# STM32F048xx register map
File version: 1.0
Registers are 32-bit, access not given, reset 0x0 unless marked. A register's access mark holds for its fields unless they carry their own. Offsets are from the block's base; [hi:lo] are bit positions; {n}, {i} and the like mark numbered series; 'fields as' and 'values as' point back to an identical list.

## PWR
Base 0x40007000
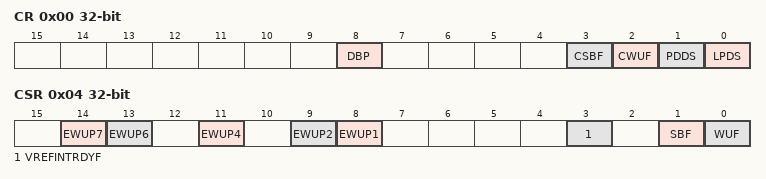
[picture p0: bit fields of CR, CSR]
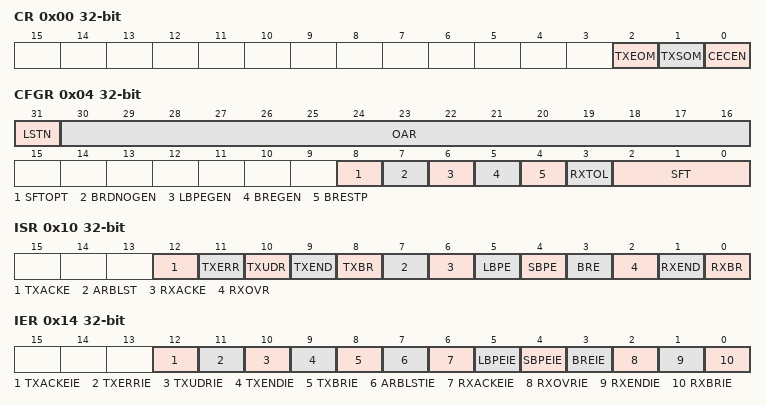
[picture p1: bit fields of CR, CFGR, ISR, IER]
0x00 CR
  [8] DBP, [3] CSBF, [2] CWUF, [1] PDDS, [0] LPDS
0x04 CSR
  [14] EWUP7, [13] EWUP6, [11] EWUP4, [9] EWUP2, [8] EWUP1, [3] VREFINTRDYF, [1] SBF, [0] WUF

## CEC
Base 0x40007800
0x00 CR
  [2] TXEOM, [1] TXSOM, [0] CECEN
0x04 CFGR
  [31] LSTN, [30:16] OAR, [8] SFTOPT, [7] BRDNOGEN, [6] LBPEGEN, [5] BREGEN, [4] BRESTP, [3] RXTOL, [2:0] SFT
0x08 TXDR
  [7:0] TXD
0x0C RXDR
0x10 ISR
  [12] TXACKE, [11] TXERR, [10] TXUDR, [9] TXEND, [8] TXBR, [7] ARBLST, [6] RXACKE, [5] LBPE, [4] SBPE, [3] BRE, [2] RXOVR, [1] RXEND, [0] RXBR
0x14 IER
  [12] TXACKEIE, [11] TXERRIE, [10] TXUDRIE, [9] TXENDIE, [8] TXBRIE, [7] ARBLSTIE, [6] RXACKEIE, [5] LBPEIE, [4] SBPEIE, [3] BREIE, [2] RXOVRIE, [1] RXENDIE, [0] RXBRIE

## SYSCFG
Base 0x40010000
0x00 CFGR1
  [23] I2C_FMP_PA10, [22] I2C_FMP_PA9, [21] I2C_FMP_I2C2, [20] I2C_FMP_I2C1, [n+10] I2C_FMP_PB{n} (n=6..9), [12] TIM17_DMA_RMP, [11] TIM16_DMA_RMP, [10] USART1RX_DMA_RMP, [9] USART1TX_DMA_RMP, [12:8] DMA_RMP, [4] PA11_PA12_RMP, [1:0] MEM_MODE
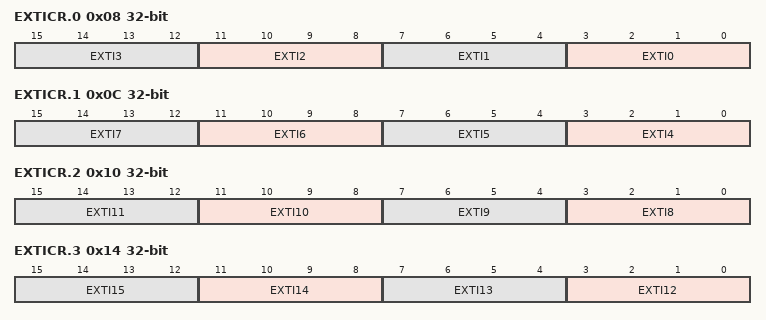
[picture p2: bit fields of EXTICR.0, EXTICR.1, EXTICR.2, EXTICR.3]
0x08 EXTICR.0
  [4n+3:4n] EXTI{n} (n=0..3)
0x0C EXTICR.1
  [4n-13:4n-16] EXTI{n} (n=4..7)
0x10 EXTICR.2
  [4n-29:4n-32] EXTI{n} (n=8..11)
0x14 EXTICR.3
  [4n-45:4n-48] EXTI{n} (n=12..15)
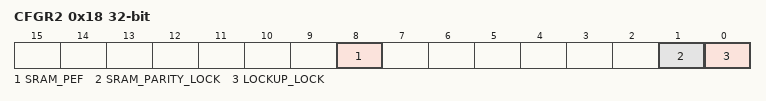
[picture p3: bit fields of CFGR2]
0x18 CFGR2
  [8] SRAM_PEF, [1] SRAM_PARITY_LOCK, [0] LOCKUP_LOCK

## EXTI
Base 0x40010400
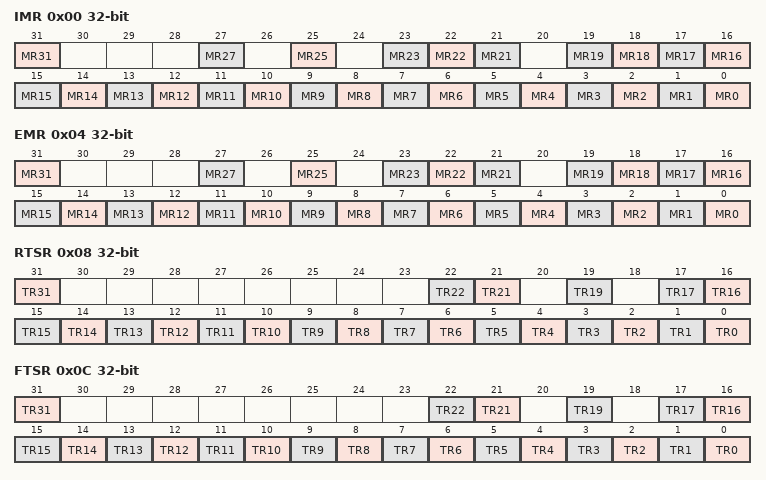
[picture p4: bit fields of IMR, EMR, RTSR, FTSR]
0x00 IMR
  [31] MR31, [27] MR27, [25] MR25, [23] MR23, [22] MR22, [21] MR21, [n] MR{n} (n=0..19)
0x04 EMR
  fields as IMR
0x08 RTSR
  [31] TR31, [22] TR22, [21] TR21, [19] TR19, [n] TR{n} (n=0..17)
0x0C FTSR
  [31] TR31, [22] TR22, [21] TR21, [19] TR19, [n] TR{n} (n=0..17)
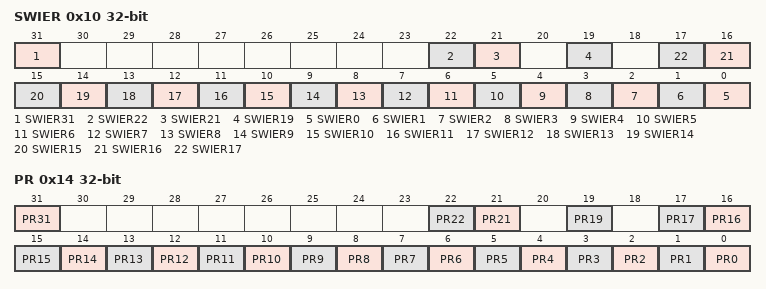
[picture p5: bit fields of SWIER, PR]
0x10 SWIER
  [31] SWIER31, [22] SWIER22, [21] SWIER21, [19] SWIER19, [n] SWIER{n} (n=0..17)
0x14 PR
  [31] PR31, [22] PR22, [21] PR21, [19] PR19, [n] PR{n} (n=0..17)

## ADC1
Base 0x40012400
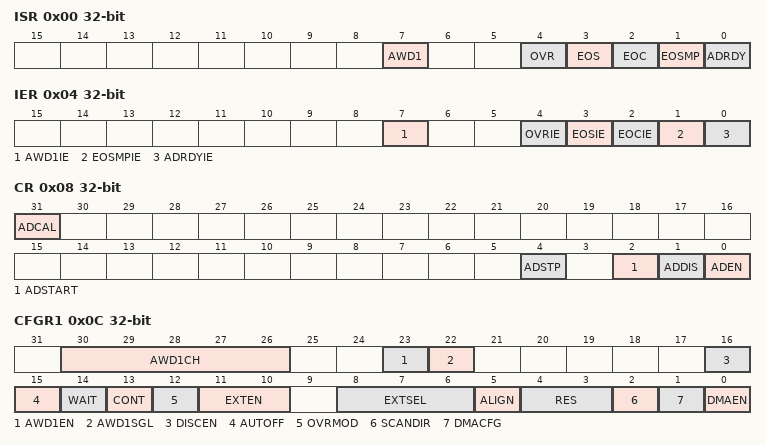
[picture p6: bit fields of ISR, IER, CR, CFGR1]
0x00 ISR
  [7] AWD1, [4] OVR, [3] EOS, [2] EOC, [1] EOSMP, [0] ADRDY
0x04 IER
  [7] AWD1IE, [4] OVRIE, [3] EOSIE, [2] EOCIE, [1] EOSMPIE, [0] ADRDYIE
0x08 CR
  [31] ADCAL, [4] ADSTP, [2] ADSTART, [1] ADDIS, [0] ADEN
0x0C CFGR1
  [30:26] AWD1CH, [23] AWD1EN, [22] AWD1SGL, [16] DISCEN, [15] AUTOFF, [14] WAIT, [13] CONT, [12] OVRMOD, [11:10] EXTEN, [8:6] EXTSEL, [5] ALIGN, [4:3] RES, [2] SCANDIR, [1] DMACFG, [0] DMAEN
0x10 CFGR2
  [31:30] CKMODE
0x14 SMPR
  [2:0] SMP
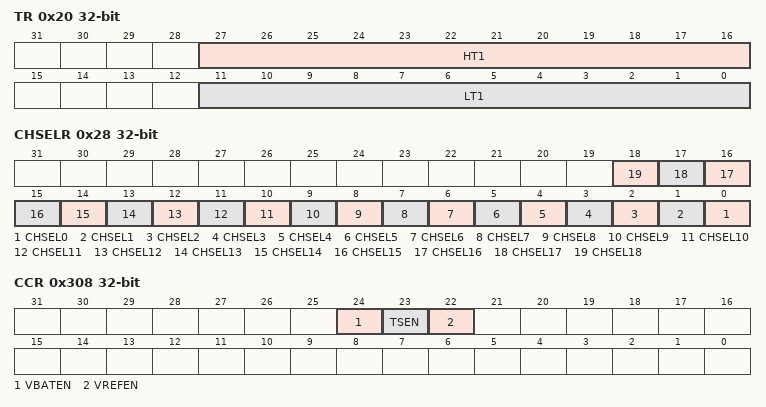
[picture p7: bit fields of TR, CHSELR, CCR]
0x20 TR
  [27:16] HT1, [11:0] LT1
0x28 CHSELR
  [n] CHSEL{n} (n=0..18)
0x40 DR
  [15:0] DATA
0x308 CCR
  [24] VBATEN, [23] TSEN, [22] VREFEN

## DBGMCU
Base 0x40015800
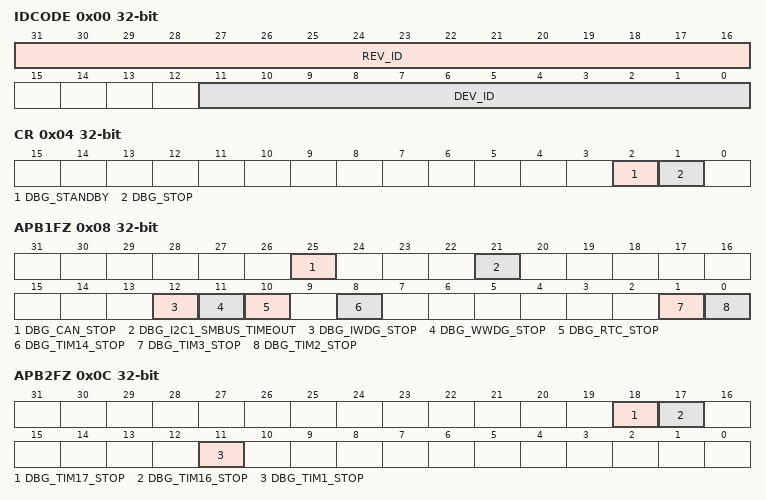
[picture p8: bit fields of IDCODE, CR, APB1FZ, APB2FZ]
0x00 IDCODE
  [31:16] REV_ID, [11:0] DEV_ID
0x04 CR
  [2] DBG_STANDBY, [1] DBG_STOP
0x08 APB1FZ
  [25] DBG_CAN_STOP, [21] DBG_I2C1_SMBUS_TIMEOUT, [12] DBG_IWDG_STOP, [11] DBG_WWDG_STOP, [10] DBG_RTC_STOP, [8] DBG_TIM14_STOP, [1] DBG_TIM3_STOP, [0] DBG_TIM2_STOP
0x0C APB2FZ
  [18] DBG_TIM17_STOP, [17] DBG_TIM16_STOP, [11] DBG_TIM1_STOP

## DMA1
Base 0x40020000
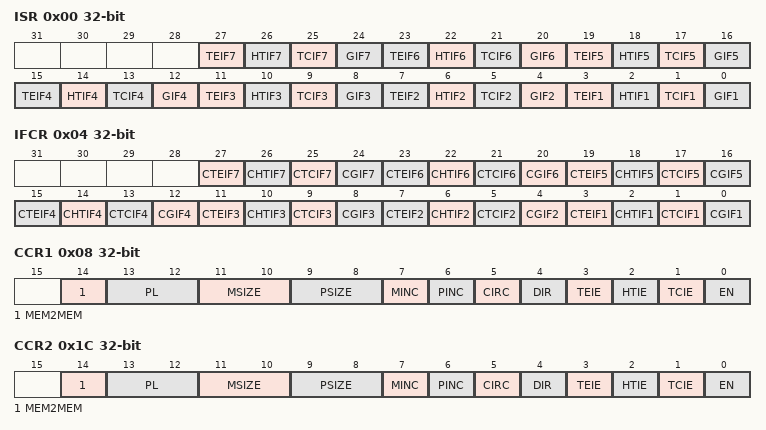
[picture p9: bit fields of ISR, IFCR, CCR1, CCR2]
0x00 ISR
  [4n-1] TEIF{n} (n=1..7), [4n-2] HTIF{n} (n=1..7), [4n-3] TCIF{n} (n=1..7), [4n-4] GIF{n} (n=1..7)
0x04 IFCR
  [4n-1] CTEIF{n} (n=1..7), [4n-2] CHTIF{n} (n=1..7), [4n-3] CTCIF{n} (n=1..7), [4n-4] CGIF{n} (n=1..7)
0x08 CCR1
  [14] MEM2MEM, [13:12] PL, [11:10] MSIZE, [9:8] PSIZE, [7] MINC, [6] PINC, [5] CIRC, [4] DIR, [3] TEIE, [2] HTIE, [1] TCIE, [0] EN
0x0C CNDTR1
  [15:0] NDT
{0x0+0x14*i} CPAR{i} (i=1..7)
  [31:0] PA
0x1C CCR2
  fields as CCR1
{0xC+0x14*i} CMAR{i} (i=1..7)
  [31:0] MA
0x20 CNDTR2
  [15:0] NDT
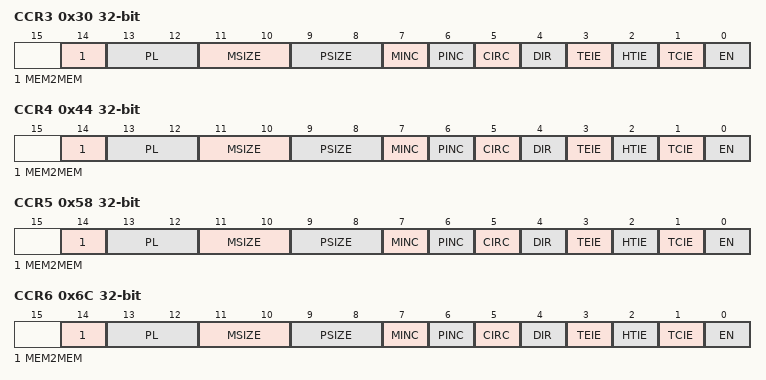
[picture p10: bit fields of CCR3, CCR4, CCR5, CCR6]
0x30 CCR3
  fields as CCR1
0x34 CNDTR3
  [15:0] NDT
0x44 CCR4
  fields as CCR1
0x48 CNDTR4
  [15:0] NDT
0x58 CCR5
  fields as CCR1
0x5C CNDTR5
  [15:0] NDT
0x6C CCR6
  fields as CCR1
0x70 CNDTR6
  [15:0] NDT
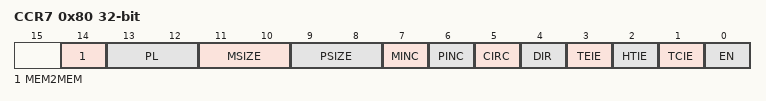
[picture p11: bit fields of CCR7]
0x80 CCR7
  fields as CCR1
0x84 CNDTR7
  [15:0] NDT

## RCC
Base 0x40021000
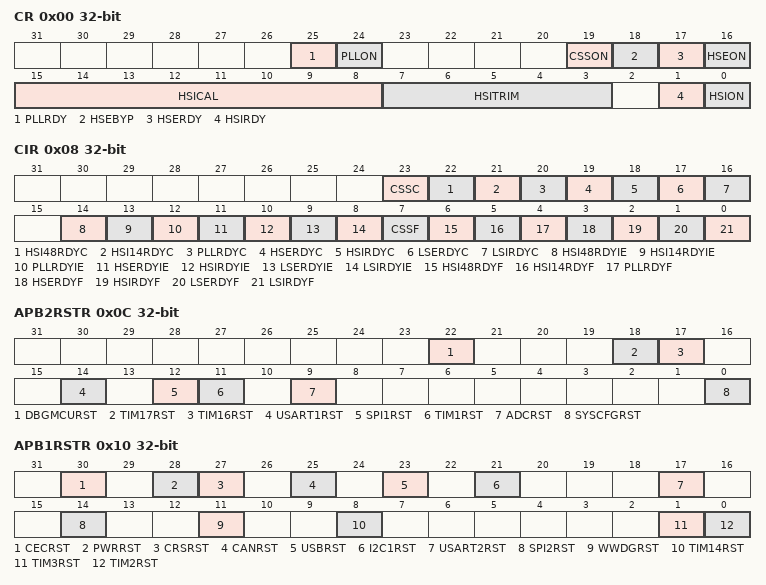
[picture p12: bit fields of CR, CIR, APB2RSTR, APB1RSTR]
0x00 CR
  [25] PLLRDY, [24] PLLON, [19] CSSON, [18] HSEBYP, [17] HSERDY, [16] HSEON, [15:8] HSICAL, [7:3] HSITRIM, [1] HSIRDY, [0] HSION
0x04 CFGR
  [31] PLLNODIV, [30:28] MCOPRE, [27:24] MCO, [22] USBPRE, [21:18] PLLMUL, [17] PLLXTPRE, [16:15] PLLSRC, [14] ADCPRE, [10] PPRE_DIV2, [10:9] PPRE_DIV8, [10:8] PPRE_DIV4, [7:4] HPRE, [3:2] SWS, [1:0] SW
0x08 CIR
  [23] CSSC, [22] HSI48RDYC, [21] HSI14RDYC, [20] PLLRDYC, [19] HSERDYC, [18] HSIRDYC, [17] LSERDYC, [16] LSIRDYC, [14] HSI48RDYIE, [13] HSI14RDYIE, [12] PLLRDYIE, [11] HSERDYIE, [10] HSIRDYIE, [9] LSERDYIE, [8] LSIRDYIE, [7] CSSF, [6] HSI48RDYF, [5] HSI14RDYF, [4] PLLRDYF, [3] HSERDYF, [2] HSIRDYF, [1] LSERDYF, [0] LSIRDYF
0x0C APB2RSTR
  [22] DBGMCURST, [18] TIM17RST, [17] TIM16RST, [14] USART1RST, [12] SPI1RST, [11] TIM1RST, [9] ADCRST, [0] SYSCFGRST
0x10 APB1RSTR
  [30] CECRST, [28] PWRRST, [27] CRSRST, [25] CANRST, [23] USBRST, [21] I2C1RST, [17] USART2RST, [14] SPI2RST, [11] WWDGRST, [8] TIM14RST, [1] TIM3RST, [0] TIM2RST
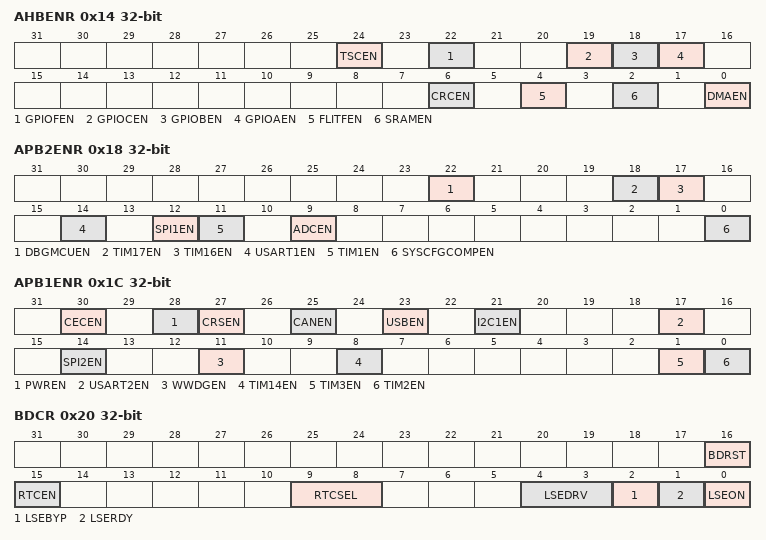
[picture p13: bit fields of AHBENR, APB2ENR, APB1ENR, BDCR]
0x14 AHBENR
  [24] TSCEN, [22] GPIOFEN, [19] GPIOCEN, [18] GPIOBEN, [17] GPIOAEN, [6] CRCEN, [4] FLITFEN, [2] SRAMEN, [0] DMAEN
0x18 APB2ENR
  [22] DBGMCUEN, [18] TIM17EN, [17] TIM16EN, [14] USART1EN, [12] SPI1EN, [11] TIM1EN, [9] ADCEN, [0] SYSCFGCOMPEN
0x1C APB1ENR
  [30] CECEN, [28] PWREN, [27] CRSEN, [25] CANEN, [23] USBEN, [21] I2C1EN, [17] USART2EN, [14] SPI2EN, [11] WWDGEN, [8] TIM14EN, [1] TIM3EN, [0] TIM2EN
0x20 BDCR
  [16] BDRST, [15] RTCEN, [9:8] RTCSEL, [4:3] LSEDRV, [2] LSEBYP, [1] LSERDY, [0] LSEON
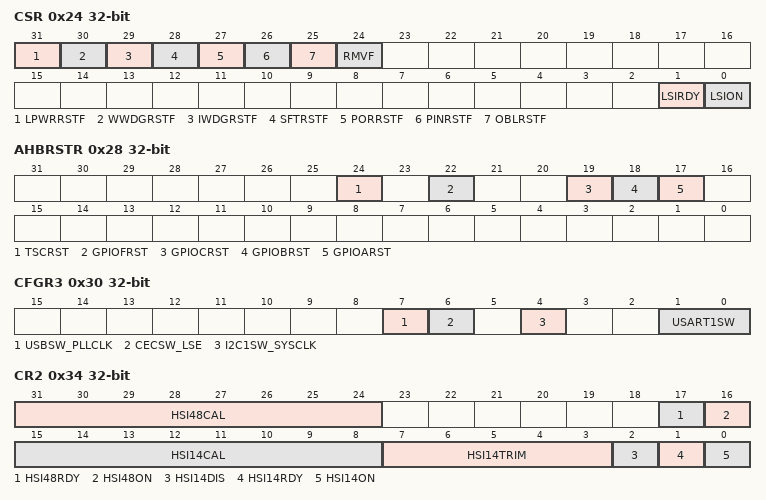
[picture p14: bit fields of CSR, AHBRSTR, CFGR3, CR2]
0x24 CSR
  [31] LPWRRSTF, [30] WWDGRSTF, [29] IWDGRSTF, [28] SFTRSTF, [27] PORRSTF, [26] PINRSTF, [25] OBLRSTF, [24] RMVF, [1] LSIRDY, [0] LSION
0x28 AHBRSTR
  [24] TSCRST, [22] GPIOFRST, [19] GPIOCRST, [18] GPIOBRST, [17] GPIOARST
0x2C CFGR2
  [3:0] PREDIV
0x30 CFGR3
  [7] USBSW_PLLCLK, [6] CECSW_LSE, [4] I2C1SW_SYSCLK, [1:0] USART1SW
0x34 CR2
  [31:24] HSI48CAL, [17] HSI48RDY, [16] HSI48ON, [15:8] HSI14CAL, [7:3] HSI14TRIM, [2] HSI14DIS, [1] HSI14RDY, [0] HSI14ON

## FLASH
Base 0x40022000
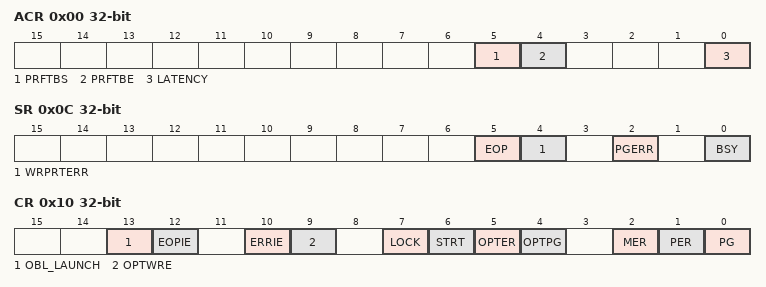
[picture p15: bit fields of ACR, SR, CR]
0x00 ACR
  [5] PRFTBS, [4] PRFTBE, [0] LATENCY
0x04 KEYR
  [31:0] FKEYR
0x08 OPTKEYR
0x0C SR
  [5] EOP, [4] WRPRTERR, [2] PGERR, [0] BSY
0x10 CR
  [13] OBL_LAUNCH, [12] EOPIE, [10] ERRIE, [9] OPTWRE, [7] LOCK, [6] STRT, [5] OPTER, [4] OPTPG, [2] MER, [1] PER, [0] PG
0x14 AR
  [31:0] FAR
0x1C OBR
  [31:24] DATA1, [23:16] DATA0, [15] BOOT_SEL, [14] RAM_PARITY_CHECK, [13] VDDA_MONITOR, [12] nBOOT1, [11] nBOOT0, [10] nRST_STDBY, [9] nRST_STOP, [15:8] USER, [2] RDPRT2, [1] RDPRT1, [0] OPTERR
0x20 WRPR
  [15:0] WRP

## CRC
Base 0x40023000
0x00 DR
0x04 IDR 8-bit
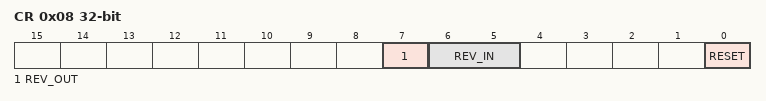
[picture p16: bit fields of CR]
0x08 CR
  [7] REV_OUT, [6:5] REV_IN, [0] RESET
0x10 INIT

## TSC
Base 0x40024000
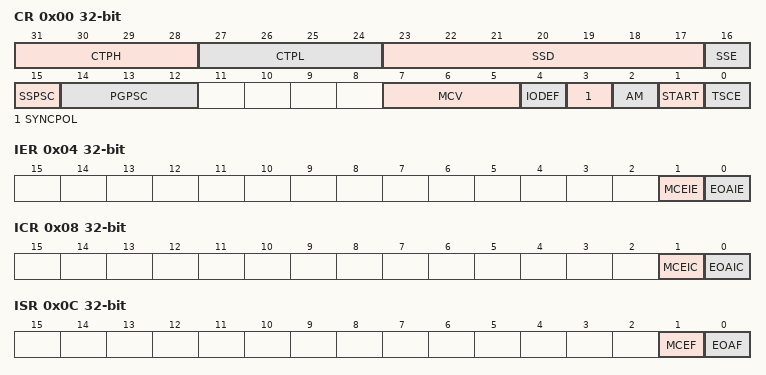
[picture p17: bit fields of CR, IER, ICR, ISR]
0x00 CR
  [31:28] CTPH, [27:24] CTPL, [23:17] SSD, [16] SSE, [15] SSPSC, [14:12] PGPSC, [7:5] MCV, [4] IODEF, [3] SYNCPOL, [2] AM, [1] START, [0] TSCE
0x04 IER
  [1] MCEIE, [0] EOAIE
0x08 ICR
  [1] MCEIC, [0] EOAIC
0x0C ISR
  [1] MCEF, [0] EOAF
0x10 IOHCR
  [4n-1] G{n}_IO4 (n=1..8), [4n-2] G{n}_IO3 (n=1..8), [4n-3] G{n}_IO2 (n=1..8), [4n-4] G{n}_IO1 (n=1..8)
0x18 IOASCR
  fields as IOHCR
0x20 IOSCR
  fields as IOHCR
0x28 IOCCR
  fields as IOHCR
0x30 IOGCSR
  [n+15] G{n}S (n=1..8), [n-1] G{n}E (n=1..8)
0x34 IOGXCR.0
  [13:0] CNT
0x38 IOGXCR.1
  [13:0] CNT
0x3C IOGXCR.2
  [13:0] CNT
0x40 IOGXCR.3
  [13:0] CNT
0x44 IOGXCR.4
  [13:0] CNT
0x48 IOGXCR.5
  [13:0] CNT
0x4C IOGXCR.6
  [13:0] CNT
0x50 IOGXCR.7
  [13:0] CNT

## GPIOA
Base 0x48000000
Same registers: GPIOB 0x48000400, GPIOC 0x48000800, GPIOF 0x48001400
0x00 MODER
  [2n+1:2n] MODER{n} (n=0..15)
0x04 OTYPER
0x08 OSPEEDR
  [2n+1:2n] OSPEEDR{n} (n=0..15)
0x0C PUPDR
  [2n+1:2n] PUPDR{n} (n=0..15)
0x10 IDR
0x14 ODR
0x18 BSRR
0x1C LCKR
  [16] LCKK, [n] LCK{n} (n=0..15)
0x20 AFR.0
  [4n+3:4n] AFSEL{n} (n=0..7)
0x24 AFR.1
  [4n-29:4n-32] AFSEL{n} (n=8..15)
0x28 BRR
